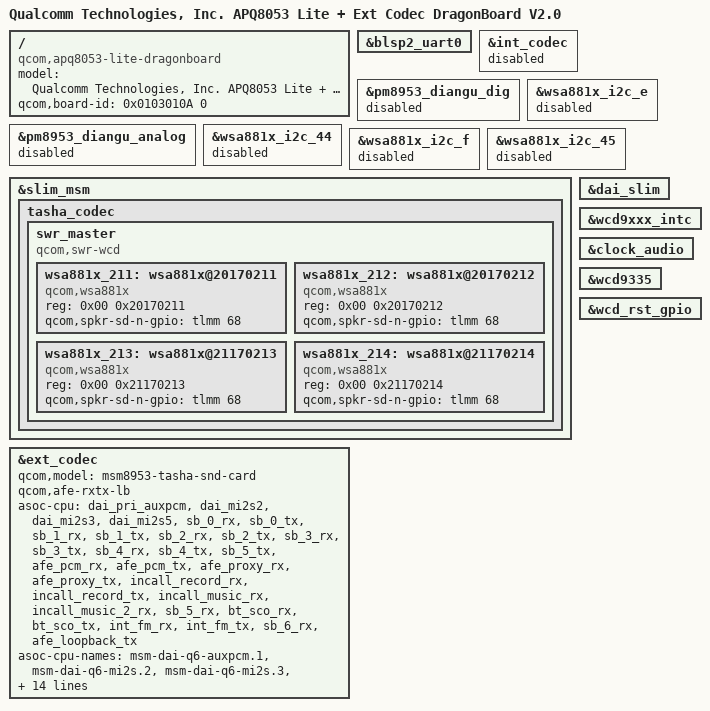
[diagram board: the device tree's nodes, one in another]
/*
 * Copyright (c) 2018, The Linux Foundation. All rights reserved.
 *
 * This program is free software; you can redistribute it and/or modify
 * it under the terms of the GNU General Public License version 2 and
 * only version 2 as published by the Free Software Foundation.
 *
 * This program is distributed in the hope that it will be useful,
 * but WITHOUT ANY WARRANTY; without even the implied warranty of
 * MERCHANTABILITY or FITNESS FOR A PARTICULAR PURPOSE.  See the
 * GNU General Public License for more details.
 */

/dts-v1/;

#include "apq8053-lite.dtsi"
#include "apq8053-lite-dragon-v2.0.dtsi"

/ {
	model = "Qualcomm Technologies, Inc. APQ8053 Lite + Ext Codec DragonBoard V2.0";
	compatible = "qcom,apq8053-lite-dragonboard",
			"qcom,apq8053", "qcom,dragonboard";
	qcom,board-id = <0x0103010A 0>;
};

&blsp2_uart0 {
	status = "okay";
};

&int_codec {
	status = "disabled";
};

&pm8953_diangu_dig {
	status = "disabled";
};

&pm8953_diangu_analog {
	status = "disabled";
};

&wsa881x_i2c_e {
	status = "disabled";
};

&wsa881x_i2c_44 {
	status = "disabled";
};

&wsa881x_i2c_f {
	status = "disabled";
};

&wsa881x_i2c_45 {
	status = "disabled";
};

&slim_msm {
	status = "okay";
	tasha_codec {
		swr_master {
			compatible = "qcom,swr-wcd";
			#address-cells = <2>;
			#size-cells = <0>;

			wsa881x_211: wsa881x@20170211 {
				compatible = "qcom,wsa881x";
				reg = <0x00 0x20170211>;
				qcom,spkr-sd-n-gpio = <&tlmm 68 0>;
			};

			wsa881x_212: wsa881x@20170212 {
				compatible = "qcom,wsa881x";
				reg = <0x00 0x20170212>;
				qcom,spkr-sd-n-gpio = <&tlmm 68 0>;
			};

			wsa881x_213: wsa881x@21170213 {
				compatible = "qcom,wsa881x";
				reg = <0x00 0x21170213>;
				qcom,spkr-sd-n-gpio = <&tlmm 68 0>;
			};

			wsa881x_214: wsa881x@21170214 {
				compatible = "qcom,wsa881x";
				reg = <0x00 0x21170214>;
				qcom,spkr-sd-n-gpio = <&tlmm 68 0>;
			};
		};
	};
};

&dai_slim {
	status = "okay";
};

&wcd9xxx_intc {
	status = "okay";
};

&clock_audio {
	status = "okay";
};

&wcd9335 {
	status = "okay";
};

&wcd_rst_gpio {
	status = "okay";
};

&ext_codec {
	qcom,model = "msm8953-tasha-snd-card";
	status = "okay";
	qcom,afe-rxtx-lb;
	asoc-cpu = <&dai_pri_auxpcm>,
			<&dai_mi2s2>, <&dai_mi2s3>, <&dai_mi2s5>,
			<&sb_0_rx>, <&sb_0_tx>, <&sb_1_rx>, <&sb_1_tx>,
			<&sb_2_rx>, <&sb_2_tx>, <&sb_3_rx>, <&sb_3_tx>,
			<&sb_4_rx>, <&sb_4_tx>, <&sb_5_tx>,
			<&afe_pcm_rx>, <&afe_pcm_tx>,
			<&afe_proxy_rx>, <&afe_proxy_tx>,
			<&incall_record_rx>, <&incall_record_tx>,
			<&incall_music_rx>, <&incall_music_2_rx>,
			<&sb_5_rx>,  <&bt_sco_rx>,
			<&bt_sco_tx>, <&int_fm_rx>, <&int_fm_tx>,
			<&sb_6_rx>, <&afe_loopback_tx>;
	asoc-cpu-names = "msm-dai-q6-auxpcm.1",
			"msm-dai-q6-mi2s.2",
			"msm-dai-q6-mi2s.3", "msm-dai-q6-mi2s.5",
			"msm-dai-q6-dev.16384", "msm-dai-q6-dev.16385",
			"msm-dai-q6-dev.16386", "msm-dai-q6-dev.16387",
			"msm-dai-q6-dev.16388", "msm-dai-q6-dev.16389",
			"msm-dai-q6-dev.16390", "msm-dai-q6-dev.16391",
			"msm-dai-q6-dev.16392", "msm-dai-q6-dev.16393",
			"msm-dai-q6-dev.16395", "msm-dai-q6-dev.224",
			"msm-dai-q6-dev.225", "msm-dai-q6-dev.241",
			"msm-dai-q6-dev.240", "msm-dai-q6-dev.32771",
			"msm-dai-q6-dev.32772", "msm-dai-q6-dev.32773",
			"msm-dai-q6-dev.32770", "msm-dai-q6-dev.16394",
			"msm-dai-q6-dev.12288", "msm-dai-q6-dev.12289",
			"msm-dai-q6-dev.12292", "msm-dai-q6-dev.12293",
			"msm-dai-q6-dev.16396", "msm-dai-q6-dev.24577";
};
